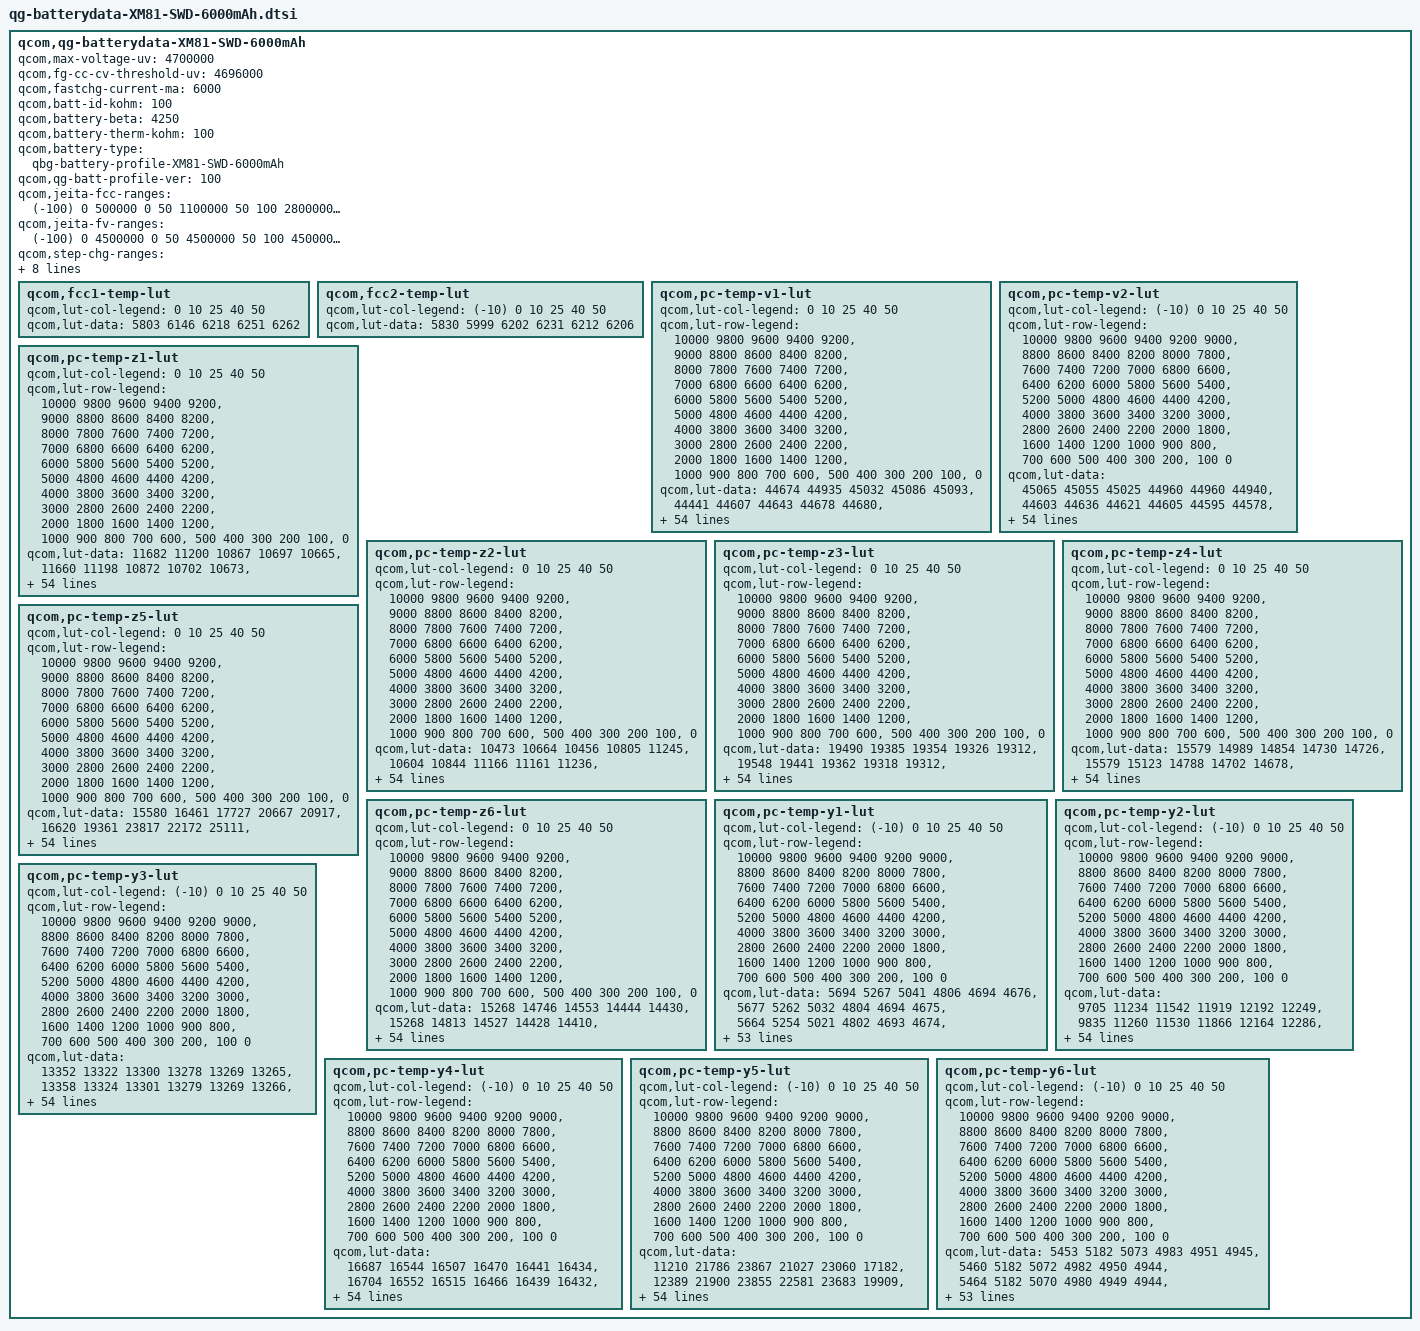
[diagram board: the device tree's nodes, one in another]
/* Copyright (c) 2018, The Linux Foundation. All rights reserved.
 *
 * This program is free software; you can redistribute it and/or modify
 * it under the terms of the GNU General Public License version 2 and
 * only version 2 as published by the Free Software Foundation.
 *
 * This program is distributed in the hope that it will be useful,
 * but WITHOUT ANY WARRANTY; without even the implied warranty of
 * MERCHANTABILITY or FITNESS FOR A PARTICULAR PURPOSE.  See the
 * GNU General Public License for more details.
 */

qcom,qg-batterydata-XM81-SWD-6000mAh {
    /* 7542751_LC_M544_Sunwoda_6000mAH_PM7250B_averaged_MasterSlave_Dec17th2024 */
    qcom,max-voltage-uv = <4700000>;
    qcom,fg-cc-cv-threshold-uv = <4696000>;
    qcom,fastchg-current-ma = <6000>;
    qcom,batt-id-kohm = <100>;
    qcom,battery-beta = <4250>;
    qcom,battery-therm-kohm = <100>;
    qcom,battery-type = "qbg-battery-profile-XM81-SWD-6000mAh";
    qcom,qg-batt-profile-ver = <100>;

    qcom,jeita-fcc-ranges = <(-100)  0   500000
				0   50   1100000
				50  100  2800000
				100 150  3600000
				150 350  6000000
				350 450  6000000
				450 550  2800000>;
	qcom,jeita-fv-ranges = <(-100)   0   4500000
				0   50   4500000
				50  100  4500000
				100 150  4500000
				150 350  4530000
				350 480  4530000
				480 550  4100000>;
	qcom,step-chg-ranges = <3600000  4250000  6000000
				4250001  4500000  5400000
				4500001  4530000  4696000>;
	qcom,vbat-avg-based-step-chg;
	qcom,taper-fcc;

    /* COOL = 15 DegC, WARM = 45 DegC */
	qcom,jeita-soft-thresholds = <0x4621 0x20B8>;
	/* COLD = -10 DegC, HOT = 58 DegC */
	qcom,jeita-hard-thresholds = <0x6226 0x15F7>;
	/* COOL hys = 18 DegC, WARM hys = 42 DegC */
	qcom,jeita-soft-hys-thresholds = <0x4621 0x23C0>;

	qcom,jeita-soft-fcc-ua = <5400000 4500000>;
	qcom,jeita-soft-fv-uv = <4650000 4530000>;

	qcom,fcc1-temp-lut {
		qcom,lut-col-legend = <0 10 25 40 50>;
		qcom,lut-data = <5803 6146 6218 6251 6262>;
	};

	qcom,fcc2-temp-lut {
		qcom,lut-col-legend = <(-10) 0 10 25 40 50>;
		qcom,lut-data = <5830 5999 6202 6231 6212 6206>;
	};

	qcom,pc-temp-v1-lut {
		qcom,lut-col-legend = <0 10 25 40 50>;
		qcom,lut-row-legend = <10000 9800 9600 9400 9200>,
			<9000 8800 8600 8400 8200>,
			<8000 7800 7600 7400 7200>,
			<7000 6800 6600 6400 6200>,
			<6000 5800 5600 5400 5200>,
			<5000 4800 4600 4400 4200>,
			<4000 3800 3600 3400 3200>,
			<3000 2800 2600 2400 2200>,
			<2000 1800 1600 1400 1200>,
			<1000 900 800 700 600>,
			<500 400 300 200 100>,
			<0>;
		qcom,lut-data = <44674 44935 45032 45086 45093>,
			<44441 44607 44643 44678 44680>,
			<44237 44380 44387 44398 44399>,
			<44041 44181 44175 44176 44175>,
			<43834 43973 43971 43967 43968>,
			<43617 43756 43753 43752 43754>,
			<43391 43530 43528 43534 43534>,
			<43156 43292 43293 43306 43305>,
			<42911 43043 43045 43060 43063>,
			<42666 42789 42791 42806 42812>,
			<42417 42528 42532 42550 42558>,
			<42170 42267 42270 42290 42301>,
			<41928 42009 42011 42033 42044>,
			<41689 41754 41754 41776 41788>,
			<41458 41507 41505 41524 41536>,
			<41233 41267 41264 41281 41294>,
			<41015 41036 41031 41044 41058>,
			<40806 40815 40806 40817 40830>,
			<40604 40605 40589 40599 40609>,
			<40408 40408 40384 40390 40398>,
			<40224 40224 40199 40199 40206>,
			<40045 40023 40001 40004 40012>,
			<39855 39797 39742 39768 39782>,
			<39651 39565 39463 39509 39528>,
			<39443 39331 39255 39292 39309>,
			<39226 39104 39092 39112 39123>,
			<39007 38942 38952 38957 38962>,
			<38853 38829 38828 38822 38825>,
			<38752 38730 38718 38703 38705>,
			<38670 38629 38613 38595 38594>,
			<38588 38534 38515 38497 38491>,
			<38511 38451 38427 38406 38396>,
			<38442 38376 38351 38323 38310>,
			<38380 38311 38282 38246 38231>,
			<38325 38254 38221 38180 38161>,
			<38275 38203 38167 38121 38096>,
			<38231 38161 38114 38058 38025>,
			<38189 38127 38068 37993 37945>,
			<38151 38080 38011 37920 37858>,
			<38112 38000 37928 37832 37766>,
			<38052 37897 37824 37729 37664>,
			<37948 37781 37708 37614 37546>,
			<37826 37643 37572 37479 37407>,
			<37692 37478 37406 37317 37243>,
			<37550 37309 37239 37157 37086>,
			<37368 37180 37122 37051 36991>,
			<37282 37141 37092 37024 36965>,
			<37213 37118 37070 37005 36950>,
			<37168 37095 37049 36990 36933>,
			<37118 37065 37015 36952 36887>,
			<37075 36923 36833 36731 36642>,
			<37030 36511 36414 36295 36198>,
			<36967 35912 35828 35707 35611>,
			<36796 35047 35020 34898 34800>,
			<36111 33648 33745 33629 33528>,
			<30000 30000 30000 30000 30000>;
	};

	qcom,pc-temp-v2-lut {
		qcom,lut-col-legend = <(-10) 0 10 25 40 50>;
		qcom,lut-row-legend = <10000 9800 9600 9400 9200 9000>,
			<8800 8600 8400 8200 8000 7800>,
			<7600 7400 7200 7000 6800 6600>,
			<6400 6200 6000 5800 5600 5400>,
			<5200 5000 4800 4600 4400 4200>,
			<4000 3800 3600 3400 3200 3000>,
			<2800 2600 2400 2200 2000 1800>,
			<1600 1400 1200 1000 900 800>,
			<700 600 500 400 300 200>,
			<100 0>;
		qcom,lut-data = <45065 45055 45025 44960 44960 44940>,
			<44603 44636 44621 44605 44595 44578>,
			<44220 44286 44282 44300 44279 44265>,
			<43944 44022 44025 44055 44025 44012>,
			<43749 43826 43827 43856 43819 43805>,
			<43564 43633 43624 43651 43609 43595>,
			<43351 43420 43403 43426 43382 43368>,
			<43129 43201 43173 43192 43147 43134>,
			<42902 42970 42931 42947 42903 42891>,
			<42669 42727 42675 42692 42649 42638>,
			<42433 42479 42418 42434 42393 42384>,
			<42197 42229 42157 42172 42134 42127>,
			<41960 41978 41898 41913 41878 41871>,
			<41723 41731 41645 41657 41625 41620>,
			<41491 41488 41396 41406 41377 41374>,
			<41258 41250 41154 41163 41137 41134>,
			<41015 41025 40915 40927 40904 40900>,
			<40764 40803 40684 40697 40679 40675>,
			<40510 40568 40469 40476 40463 40461>,
			<40247 40321 40255 40259 40252 40254>,
			<39986 40069 40010 40041 40051 40055>,
			<39745 39804 39742 39825 39856 39863>,
			<39522 39543 39488 39590 39637 39646>,
			<39315 39319 39245 39318 39357 39369>,
			<39122 39120 39029 39077 39102 39113>,
			<38942 38943 38855 38904 38928 38939>,
			<38778 38782 38708 38759 38788 38800>,
			<38629 38636 38573 38627 38659 38672>,
			<38491 38504 38449 38508 38542 38554>,
			<38356 38385 38335 38398 38435 38446>,
			<38227 38273 38231 38296 38338 38346>,
			<38122 38164 38134 38202 38248 38254>,
			<38042 38062 38044 38117 38166 38171>,
			<37974 37976 37961 38038 38092 38099>,
			<37908 37899 37886 37962 38013 38018>,
			<37848 37835 37823 37889 37930 37921>,
			<37787 37788 37763 37813 37841 37816>,
			<37725 37747 37703 37726 37738 37702>,
			<37661 37697 37643 37634 37627 37582>,
			<37593 37638 37569 37542 37526 37476>,
			<37521 37566 37475 37452 37440 37388>,
			<37442 37469 37356 37338 37335 37283>,
			<37355 37348 37204 37201 37207 37153>,
			<37258 37210 37043 37053 37076 37020>,
			<37147 37057 36846 36903 36916 36864>,
			<37029 36889 36714 36859 36880 36832>,
			<36971 36803 36659 36835 36866 36818>,
			<36910 36727 36589 36802 36848 36800>,
			<36848 36662 36491 36743 36821 36771>,
			<36791 36598 36298 36570 36731 36674>,
			<36723 36471 35860 36145 36433 36344>,
			<36633 36302 35179 35495 35904 35813>,
			<36483 35868 34414 34584 35206 35110>,
			<36202 35807 33567 33153 34198 34097>,
			<36209 35316 32223 31541 32692 32531>,
			<35983 34759 28774 28591 27756 27768>;
	};

	qcom,pc-temp-z1-lut {
		qcom,lut-col-legend = <0 10 25 40 50>;
		qcom,lut-row-legend = <10000 9800 9600 9400 9200>,
			<9000 8800 8600 8400 8200>,
			<8000 7800 7600 7400 7200>,
			<7000 6800 6600 6400 6200>,
			<6000 5800 5600 5400 5200>,
			<5000 4800 4600 4400 4200>,
			<4000 3800 3600 3400 3200>,
			<3000 2800 2600 2400 2200>,
			<2000 1800 1600 1400 1200>,
			<1000 900 800 700 600>,
			<500 400 300 200 100>,
			<0>;
		qcom,lut-data = <11682 11200 10867 10697 10665>,
			<11660 11198 10872 10702 10673>,
			<11646 11191 10854 10695 10669>,
			<11634 11178 10842 10690 10668>,
			<11626 11166 10831 10687 10667>,
			<11619 11155 10824 10687 10668>,
			<11613 11142 10817 10687 10671>,
			<11604 11123 10813 10687 10673>,
			<11592 11104 10809 10685 10671>,
			<11576 11095 10807 10683 10668>,
			<11547 11091 10804 10682 10668>,
			<11523 11089 10802 10681 10668>,
			<11517 11089 10801 10681 10668>,
			<11515 11088 10799 10680 10668>,
			<11512 11087 10799 10680 10669>,
			<11508 11082 10798 10680 10669>,
			<11505 11080 10798 10681 10670>,
			<11507 11080 10799 10681 10671>,
			<11517 11082 10801 10683 10672>,
			<11526 11084 10803 10684 10673>,
			<11527 11088 10805 10685 10674>,
			<11527 11092 10806 10687 10676>,
			<11529 11099 10808 10688 10677>,
			<11534 11105 10811 10689 10678>,
			<11537 11108 10814 10690 10679>,
			<11537 11109 10817 10693 10682>,
			<11536 11113 10821 10695 10684>,
			<11537 11122 10824 10698 10686>,
			<11554 11130 10829 10701 10687>,
			<11574 11134 10833 10703 10689>,
			<11577 11136 10838 10706 10691>,
			<11575 11139 10842 10708 10693>,
			<11575 11143 10846 10710 10694>,
			<11584 11146 10849 10712 10696>,
			<11598 11148 10853 10715 10698>,
			<11602 11153 10858 10718 10700>,
			<11598 11157 10862 10721 10701>,
			<11596 11167 10867 10725 10703>,
			<11607 11177 10872 10728 10705>,
			<11629 11190 10878 10731 10707>,
			<11650 11202 10884 10733 10709>,
			<11673 11205 10890 10735 10711>,
			<11685 11207 10896 10738 10713>,
			<11684 11221 10902 10740 10714>,
			<11728 11240 10910 10742 10716>,
			<11723 11245 10917 10744 10716>,
			<11726 11245 10916 10745 10717>,
			<11722 11239 10915 10745 10717>,
			<11704 11241 10921 10747 10718>,
			<11731 11242 10922 10750 10720>,
			<11711 11257 10929 10752 10722>,
			<11717 11255 10939 10758 10725>,
			<11734 11268 10950 10763 10730>,
			<11745 11292 10965 10772 10737>,
			<11745 11292 10965 10772 10737>,
			<11745 11292 10965 10772 10737>;
	};

	qcom,pc-temp-z2-lut {
		qcom,lut-col-legend = <0 10 25 40 50>;
		qcom,lut-row-legend = <10000 9800 9600 9400 9200>,
			<9000 8800 8600 8400 8200>,
			<8000 7800 7600 7400 7200>,
			<7000 6800 6600 6400 6200>,
			<6000 5800 5600 5400 5200>,
			<5000 4800 4600 4400 4200>,
			<4000 3800 3600 3400 3200>,
			<3000 2800 2600 2400 2200>,
			<2000 1800 1600 1400 1200>,
			<1000 900 800 700 600>,
			<500 400 300 200 100>,
			<0>;
		qcom,lut-data = <10473 10664 10456 10805 11245>,
			<10604 10844 11166 11161 11236>,
			<10612 10918 11296 11499 11322>,
			<10605 10880 11235 11493 11306>,
			<10589 10842 11149 11449 11270>,
			<10562 10799 11087 11381 11262>,
			<10537 10761 11032 11264 11270>,
			<10521 10735 11020 11183 11275>,
			<10508 10716 11021 11141 11281>,
			<10505 10717 11023 11117 11293>,
			<10506 10745 11028 11122 11305>,
			<10508 10773 11035 11142 11317>,
			<10518 10786 11040 11166 11326>,
			<10543 10797 11052 11194 11332>,
			<10565 10809 11057 11221 11340>,
			<10580 10822 11048 11248 11370>,
			<10593 10834 11037 11275 11418>,
			<10608 10844 11039 11290 11451>,
			<10623 10855 11052 11305 11476>,
			<10639 10946 11055 11315 11497>,
			<10731 11176 11047 11320 11528>,
			<10879 11254 11049 11326 11568>,
			<10912 11087 11126 11339 11633>,
			<10795 10922 11245 11363 11728>,
			<10690 10898 11234 11397 11745>,
			<10696 10880 11073 11461 11598>,
			<10717 10876 10986 11499 11428>,
			<10723 10883 11104 11460 11309>,
			<10712 10889 11248 11374 11216>,
			<10701 10892 11235 11276 11204>,
			<10701 10897 11151 11149 11214>,
			<10708 10900 11108 11100 11229>,
			<10713 10902 11096 11131 11278>,
			<10718 10906 11090 11184 11348>,
			<10723 10916 11104 11241 11425>,
			<10728 10929 11138 11309 11521>,
			<10736 10935 11162 11365 11590>,
			<10741 10938 11180 11411 11651>,
			<10740 10943 11197 11455 11700>,
			<10738 10952 11216 11512 11737>,
			<10738 10959 11231 11563 11765>,
			<10746 10952 11220 11564 11763>,
			<10751 10936 11186 11546 11742>,
			<10753 10934 11187 11531 11715>,
			<11041 10972 11214 11532 11688>,
			<10965 11065 11226 11571 11669>,
			<10958 11059 11179 11553 11677>,
			<10959 11083 11145 11519 11715>,
			<10956 11258 11128 11565 11809>,
			<10903 11844 11124 11665 11887>,
			<10816 11267 11252 11518 11507>,
			<10511 11190 11184 11297 11266>,
			<10465 11018 11098 11202 11195>,
			<10492 10800 10922 11073 11073>,
			<10492 10800 10922 11073 11073>,
			<10492 10800 10922 11073 11073>;
	};

	qcom,pc-temp-z3-lut {
		qcom,lut-col-legend = <0 10 25 40 50>;
		qcom,lut-row-legend = <10000 9800 9600 9400 9200>,
			<9000 8800 8600 8400 8200>,
			<8000 7800 7600 7400 7200>,
			<7000 6800 6600 6400 6200>,
			<6000 5800 5600 5400 5200>,
			<5000 4800 4600 4400 4200>,
			<4000 3800 3600 3400 3200>,
			<3000 2800 2600 2400 2200>,
			<2000 1800 1600 1400 1200>,
			<1000 900 800 700 600>,
			<500 400 300 200 100>,
			<0>;
		qcom,lut-data = <19490 19385 19354 19326 19312>,
			<19548 19441 19362 19318 19312>,
			<19559 19458 19385 19335 19316>,
			<19565 19461 19384 19338 19319>,
			<19568 19461 19383 19339 19319>,
			<19570 19460 19383 19338 19319>,
			<19571 19458 19383 19334 19319>,
			<19569 19456 19383 19331 19319>,
			<19565 19452 19377 19329 19318>,
			<19560 19447 19370 19328 19317>,
			<19555 19438 19365 19325 19315>,
			<19549 19431 19361 19321 19311>,
			<19542 19428 19358 19318 19309>,
			<19535 19426 19356 19317 19308>,
			<19528 19423 19354 19316 19307>,
			<19523 19421 19348 19314 19305>,
			<19519 19418 19343 19311 19302>,
			<19514 19415 19342 19310 19300>,
			<19508 19412 19342 19307 19298>,
			<19506 19412 19341 19306 19297>,
			<19509 19416 19340 19304 19295>,
			<19514 19417 19339 19303 19294>,
			<19516 19420 19345 19304 19294>,
			<19515 19422 19356 19307 19296>,
			<19515 19421 19356 19309 19300>,
			<19518 19419 19343 19311 19310>,
			<19523 19417 19336 19314 19317>,
			<19524 19414 19341 19322 19317>,
			<19520 19412 19349 19332 19317>,
			<19515 19414 19355 19332 19316>,
			<19513 19419 19361 19325 19313>,
			<19512 19420 19363 19320 19310>,
			<19511 19420 19360 19317 19306>,
			<19511 19419 19356 19315 19302>,
			<19510 19419 19353 19311 19299>,
			<19509 19418 19352 19308 19295>,
			<19508 19417 19350 19307 19294>,
			<19507 19415 19349 19307 19294>,
			<19505 19414 19348 19307 19295>,
			<19501 19411 19346 19307 19295>,
			<19497 19408 19343 19307 19296>,
			<19492 19407 19341 19307 19297>,
			<19487 19405 19340 19305 19298>,
			<19483 19403 19339 19305 19301>,
			<19395 19395 19338 19305 19302>,
			<19439 19384 19333 19301 19294>,
			<19439 19383 19329 19300 19293>,
			<19418 19373 19328 19299 19289>,
			<19307 19339 19328 19296 19285>,
			<19294 19302 19328 19292 19286>,
			<19288 19342 19320 19300 19297>,
			<19271 19334 19324 19307 19302>,
			<19283 19354 19329 19310 19302>,
			<19330 19405 19339 19312 19303>,
			<19330 19405 19339 19312 19303>,
			<19330 19405 19339 19312 19303>;
	};

	qcom,pc-temp-z4-lut {
		qcom,lut-col-legend = <0 10 25 40 50>;
		qcom,lut-row-legend = <10000 9800 9600 9400 9200>,
			<9000 8800 8600 8400 8200>,
			<8000 7800 7600 7400 7200>,
			<7000 6800 6600 6400 6200>,
			<6000 5800 5600 5400 5200>,
			<5000 4800 4600 4400 4200>,
			<4000 3800 3600 3400 3200>,
			<3000 2800 2600 2400 2200>,
			<2000 1800 1600 1400 1200>,
			<1000 900 800 700 600>,
			<500 400 300 200 100>,
			<0>;
		qcom,lut-data = <15579 14989 14854 14730 14726>,
			<15579 15123 14788 14702 14678>,
			<15423 15165 14887 14744 14698>,
			<15209 15000 14845 14737 14703>,
			<15079 14894 14788 14716 14693>,
			<14992 14837 14756 14700 14682>,
			<14924 14796 14732 14688 14670>,
			<14872 14763 14713 14678 14662>,
			<14830 14738 14699 14672 14657>,
			<14798 14720 14689 14667 14654>,
			<14772 14706 14682 14663 14651>,
			<14751 14696 14677 14660 14648>,
			<14734 14688 14671 14655 14645>,
			<14719 14683 14663 14650 14641>,
			<14710 14677 14659 14645 14636>,
			<14706 14673 14657 14640 14633>,
			<14702 14669 14655 14636 14630>,
			<14700 14668 14651 14633 14627>,
			<14698 14666 14647 14630 14623>,
			<14695 14659 14644 14627 14621>,
			<14684 14647 14643 14626 14620>,
			<14669 14644 14642 14625 14619>,
			<14666 14658 14661 14641 14631>,
			<14680 14679 14698 14681 14666>,
			<14699 14705 14721 14694 14677>,
			<14722 14736 14737 14696 14671>,
			<14752 14742 14743 14696 14663>,
			<14762 14731 14729 14682 14655>,
			<14756 14717 14707 14660 14647>,
			<14747 14705 14690 14651 14641>,
			<14740 14694 14674 14647 14636>,
			<14733 14688 14666 14644 14633>,
			<14727 14683 14661 14640 14630>,
			<14722 14682 14659 14636 14627>,
			<14718 14681 14659 14634 14626>,
			<14715 14681 14659 14633 14624>,
			<14712 14680 14659 14634 14625>,
			<14709 14677 14660 14639 14632>,
			<14701 14674 14662 14644 14638>,
			<14690 14672 14665 14646 14637>,
			<14681 14670 14668 14647 14636>,
			<14675 14664 14665 14645 14633>,
			<14667 14654 14656 14639 14627>,
			<14653 14648 14652 14638 14627>,
			<14702 14639 14646 14638 14627>,
			<14642 14627 14634 14630 14622>,
			<14642 14624 14631 14625 14618>,
			<14667 14629 14623 14615 14612>,
			<14792 14662 14613 14607 14603>,
			<14805 14701 14612 14609 14602>,
			<14809 14660 14633 14614 14605>,
			<14827 14677 14634 14612 14605>,
			<14817 14663 14631 14610 14606>,
			<14784 14637 14625 14609 14607>,
			<14784 14637 14625 14609 14607>,
			<14784 14637 14625 14609 14607>;
	};

	qcom,pc-temp-z5-lut {
		qcom,lut-col-legend = <0 10 25 40 50>;
		qcom,lut-row-legend = <10000 9800 9600 9400 9200>,
			<9000 8800 8600 8400 8200>,
			<8000 7800 7600 7400 7200>,
			<7000 6800 6600 6400 6200>,
			<6000 5800 5600 5400 5200>,
			<5000 4800 4600 4400 4200>,
			<4000 3800 3600 3400 3200>,
			<3000 2800 2600 2400 2200>,
			<2000 1800 1600 1400 1200>,
			<1000 900 800 700 600>,
			<500 400 300 200 100>,
			<0>;
		qcom,lut-data = <15580 16461 17727 20667 20917>,
			<16620 19361 23817 22172 25111>,
			<17484 18786 21345 23631 25185>,
			<18295 20058 21721 24185 25284>,
			<19210 21233 22363 25270 25492>,
			<20269 22284 23229 25357 25939>,
			<21344 23272 24369 24964 27132>,
			<22356 24159 25005 24789 28263>,
			<23343 24965 25376 25516 29160>,
			<24301 25599 25572 26308 29778>,
			<25251 26065 25513 26041 29478>,
			<26301 26611 25381 25257 28440>,
			<27704 27465 25772 25143 28191>,
			<29428 28513 27332 26300 29794>,
			<30537 29603 28075 27443 31148>,
			<31125 30800 27153 28134 30843>,
			<31460 31732 26135 28714 30245>,
			<31456 32257 26690 28861 30399>,
			<31530 32851 28579 29362 31957>,
			<31983 34598 30131 30125 33491>,
			<34655 38344 31152 31735 34761>,
			<39487 42409 32678 33085 35644>,
			<43566 48921 40344 32520 33836>,
			<47771 53672 51373 30474 28340>,
			<51491 50933 50014 27775 25328>,
			<54343 43524 33302 23039 23995>,
			<56767 37951 24073 20196 23392>,
			<57128 33307 24245 23459 24500>,
			<51061 30946 24668 28638 26998>,
			<44373 32648 26653 29768 29339>,
			<43615 36419 32151 29933 31860>,
			<43964 39849 36649 30310 33575>,
			<44320 43376 39610 32889 34980>,
			<45137 46388 42342 36154 35991>,
			<46326 49183 45799 38276 36659>,
			<47029 51221 49081 40101 38098>,
			<47683 51250 49661 40466 38080>,
			<48142 50478 48934 39880 36324>,
			<48203 49644 47674 38929 34738>,
			<48101 48246 43237 36821 34016>,
			<48031 46876 37678 34089 33545>,
			<47552 46472 35964 32789 34413>,
			<47119 46466 35249 32061 37662>,
			<47503 45295 34414 30799 38392>,
			<30145 44557 34161 29238 37152>,
			<40211 44759 35993 27811 29080>,
			<40216 43830 33484 28825 29857>,
			<31803 31167 33710 33765 29793>,
			<12882 17783 39173 35190 35745>,
			<12405 13698 38956 30591 36336>,
			<12202 19775 24341 27961 41555>,
			<11792 16562 22752 31195 45204>,
			<12007 23678 23798 33528 41673>,
			<13774 61510 29494 35807 40428>,
			<13774 61510 29494 35807 40428>,
			<13774 61510 29494 35807 40428>;
	};

	qcom,pc-temp-z6-lut {
		qcom,lut-col-legend = <0 10 25 40 50>;
		qcom,lut-row-legend = <10000 9800 9600 9400 9200>,
			<9000 8800 8600 8400 8200>,
			<8000 7800 7600 7400 7200>,
			<7000 6800 6600 6400 6200>,
			<6000 5800 5600 5400 5200>,
			<5000 4800 4600 4400 4200>,
			<4000 3800 3600 3400 3200>,
			<3000 2800 2600 2400 2200>,
			<2000 1800 1600 1400 1200>,
			<1000 900 800 700 600>,
			<500 400 300 200 100>,
			<0>;
		qcom,lut-data = <15268 14746 14553 14444 14430>,
			<15268 14813 14527 14428 14410>,
			<15189 14832 14577 14454 14420>,
			<15076 14751 14556 14452 14424>,
			<15004 14696 14527 14444 14419>,
			<14954 14664 14512 14436 14415>,
			<14912 14639 14500 14428 14410>,
			<14876 14618 14489 14423 14406>,
			<14845 14601 14478 14419 14404>,
			<14819 14586 14470 14416 14401>,
			<14796 14574 14464 14412 14399>,
			<14777 14565 14459 14408 14396>,
			<14761 14559 14454 14405 14393>,
			<14747 14554 14450 14402 14391>,
			<14739 14550 14446 14399 14388>,
			<14733 14546 14442 14395 14385>,
			<14729 14543 14439 14392 14383>,
			<14726 14541 14436 14390 14380>,
			<14723 14538 14435 14387 14378>,
			<14721 14536 14433 14386 14376>,
			<14720 14534 14432 14385 14375>,
			<14718 14534 14432 14384 14374>,
			<14719 14542 14444 14391 14379>,
			<14726 14553 14468 14409 14396>,
			<14736 14566 14475 14418 14404>,
			<14750 14579 14476 14421 14406>,
			<14767 14581 14477 14422 14408>,
			<14773 14576 14474 14421 14406>,
			<14771 14571 14470 14417 14402>,
			<14767 14569 14467 14413 14398>,
			<14765 14568 14464 14409 14395>,
			<14763 14567 14462 14405 14392>,
			<14761 14566 14459 14402 14389>,
			<14762 14566 14457 14399 14386>,
			<14763 14567 14457 14397 14383>,
			<14764 14568 14457 14395 14381>,
			<14766 14569 14457 14395 14381>,
			<14768 14569 14458 14397 14384>,
			<14769 14570 14459 14400 14387>,
			<14770 14571 14461 14401 14387>,
			<14771 14572 14462 14402 14387>,
			<14773 14571 14461 14401 14387>,
			<14776 14570 14458 14398 14385>,
			<14779 14569 14457 14399 14386>,
			<14769 14567 14456 14399 14387>,
			<14771 14560 14450 14393 14381>,
			<14775 14559 14448 14391 14379>,
			<14776 14555 14444 14387 14375>,
			<14773 14554 14440 14381 14369>,
			<14775 14554 14441 14381 14369>,
			<14775 14561 14448 14388 14377>,
			<14778 14568 14454 14391 14380>,
			<14787 14579 14458 14393 14382>,
			<14804 14602 14465 14396 14384>,
			<14804 14602 14465 14396 14384>,
			<14804 14602 14465 14396 14384>;
	};

	qcom,pc-temp-y1-lut {
		qcom,lut-col-legend = <(-10) 0 10 25 40 50>;
		qcom,lut-row-legend = <10000 9800 9600 9400 9200 9000>,
			<8800 8600 8400 8200 8000 7800>,
			<7600 7400 7200 7000 6800 6600>,
			<6400 6200 6000 5800 5600 5400>,
			<5200 5000 4800 4600 4400 4200>,
			<4000 3800 3600 3400 3200 3000>,
			<2800 2600 2400 2200 2000 1800>,
			<1600 1400 1200 1000 900 800>,
			<700 600 500 400 300 200>,
			<100 0>;
		qcom,lut-data = <5694 5267 5041 4806 4694 4676>,
			<5677 5262 5032 4804 4694 4675>,
			<5664 5254 5021 4802 4693 4674>,
			<5656 5246 5009 4799 4692 4672>,
			<5649 5240 5000 4796 4691 4671>,
			<5645 5237 4998 4794 4690 4670>,
			<5643 5237 4999 4791 4688 4670>,
			<5644 5238 5001 4788 4686 4670>,
			<5646 5239 4998 4785 4685 4670>,
			<5656 5242 4991 4783 4683 4670>,
			<5665 5244 4987 4781 4682 4670>,
			<5663 5245 4985 4780 4682 4669>,
			<5654 5247 4983 4779 4681 4669>,
			<5645 5245 4982 4776 4680 4669>,
			<5634 5236 4981 4773 4679 4669>,
			<5626 5230 4978 4772 4679 4669>,
			<5626 5235 4975 4771 4680 4669>,
			<5631 5243 4974 4771 4680 4669>,
			<5635 5245 4976 4772 4680 4670>,
			<5640 5246 4980 4773 4680 4670>,
			<5646 5246 4979 4772 4680 4670>,
			<5647 5241 4976 4771 4680 4671>,
			<5643 5233 4975 4771 4680 4671>,
			<5641 5234 4981 4773 4681 4672>,
			<5643 5241 4987 4775 4683 4673>,
			<5649 5247 4989 4777 4684 4673>,
			<5653 5249 4989 4778 4685 4674>,
			<5656 5249 4989 4779 4686 4674>,
			<5658 5250 4990 4781 4687 4675>,
			<5657 5248 4991 4783 4688 4677>,
			<5657 5249 4992 4785 4689 4678>,
			<5657 5255 4994 4788 4690 4679>,
			<5664 5262 4997 4789 4692 4680>,
			<5672 5262 5001 4791 4694 4681>,
			<5672 5258 5004 4793 4695 4682>,
			<5665 5254 5007 4796 4696 4683>,
			<5657 5257 5009 4799 4697 4683>,
			<5650 5262 5010 4801 4698 4684>,
			<5644 5266 5011 4803 4699 4685>,
			<5644 5272 5013 4806 4700 4686>,
			<5653 5276 5015 4809 4702 4687>,
			<5660 5276 5019 4810 4703 4688>,
			<5663 5278 5028 4811 4704 4689>,
			<5667 5290 5030 4816 4704 4690>,
			<5672 5282 5035 4817 4707 4692>,
			<5673 5282 5048 4821 4709 4692>,
			<5666 5290 5040 4823 4710 4692>,
			<5667 5294 5055 4829 4711 4693>,
			<5675 5304 5069 4832 4711 4693>,
			<5714 5365 5164 4837 4711 4693>,
			<5817 5438 5246 4850 4712 4695>,
			<5886 5503 5310 4866 4715 4697>,
			<5979 5581 5310 4889 4720 4700>,
			<6001 5581 5310 4971 4725 4705>,
			<6001 5581 5310 4971 4725 4705>,
			<6001 5581 5310 4971 4725 4705>;
	};

	qcom,pc-temp-y2-lut {
		qcom,lut-col-legend = <(-10) 0 10 25 40 50>;
		qcom,lut-row-legend = <10000 9800 9600 9400 9200 9000>,
			<8800 8600 8400 8200 8000 7800>,
			<7600 7400 7200 7000 6800 6600>,
			<6400 6200 6000 5800 5600 5400>,
			<5200 5000 4800 4600 4400 4200>,
			<4000 3800 3600 3400 3200 3000>,
			<2800 2600 2400 2200 2000 1800>,
			<1600 1400 1200 1000 900 800>,
			<700 600 500 400 300 200>,
			<100 0>;
		qcom,lut-data = <9705 11234 11542 11919 12192 12249>,
			<9835 11260 11530 11866 12164 12286>,
			<10117 11270 11514 11803 12125 12295>,
			<10453 11269 11494 11741 12080 12282>,
			<10744 11259 11471 11690 12031 12252>,
			<10891 11244 11446 11660 11979 12212>,
			<10898 11216 11418 11646 11909 12127>,
			<10900 11180 11388 11632 11853 12032>,
			<10903 11152 11351 11591 11841 11970>,
			<10913 11127 11309 11527 11842 11920>,
			<10926 11116 11291 11510 11835 11898>,
			<10940 11118 11283 11516 11798 11904>,
			<10956 11126 11280 11523 11771 11913>,
			<10976 11137 11290 11527 11781 11891>,
			<11007 11162 11313 11530 11802 11853>,
			<11041 11195 11336 11547 11810 11847>,
			<11068 11237 11368 11584 11808 11860>,
			<11093 11284 11407 11633 11805 11868>,
			<11106 11317 11480 11703 11807 11882>,
			<11109 11348 11547 11786 11822 11908>,
			<11110 11362 11550 11875 11924 11939>,
			<11115 11340 11537 11967 12156 11989>,
			<11134 11304 11533 11981 12236 12056>,
			<11149 11310 11546 11883 12187 12172>,
			<11149 11374 11567 11797 12143 12289>,
			<11148 11426 11591 11787 12163 12363>,
			<11146 11441 11620 11794 12215 12424>,
			<11132 11451 11636 11821 12253 12468>,
			<11109 11462 11648 11895 12281 12506>,
			<11087 11476 11658 11933 12306 12550>,
			<11060 11482 11677 11922 12326 12639>,
			<11004 11480 11698 11910 12347 12728>,
			<10572 11473 11698 11940 12383 12730>,
			<10025 11437 11684 12027 12435 12692>,
			<9856 11261 11669 12052 12456 12675>,
			<9789 11128 11649 11988 12420 12699>,
			<9749 11175 11619 11924 12384 12724>,
			<9725 11266 11559 11900 12399 12694>,
			<9707 11252 11453 11883 12429 12610>,
			<9695 11162 11384 11891 12423 12574>,
			<9686 11036 11355 11939 12317 12577>,
			<9680 10791 11291 11936 12284 12554>,
			<9675 10463 11121 11900 12323 12479>,
			<9671 9962 10920 11877 12326 12439>,
			<9667 9743 10369 11747 12344 12457>,
			<9664 9693 9964 11672 12216 12265>,
			<9662 9678 9776 11677 12222 12151>,
			<9660 9667 9680 11649 12066 12049>,
			<9657 9659 9657 11610 11984 12055>,
			<9653 9652 9652 11452 11951 11869>,
			<9650 9649 9651 11198 11820 11797>,
			<9648 9649 9650 10852 11720 11760>,
			<9648 9650 9651 10286 11615 11619>,
			<9649 9653 9652 9708 11487 11461>,
			<9649 9653 9652 9708 11487 11461>,
			<9649 9653 9652 9708 11487 11461>;
	};

	qcom,pc-temp-y3-lut {
		qcom,lut-col-legend = <(-10) 0 10 25 40 50>;
		qcom,lut-row-legend = <10000 9800 9600 9400 9200 9000>,
			<8800 8600 8400 8200 8000 7800>,
			<7600 7400 7200 7000 6800 6600>,
			<6400 6200 6000 5800 5600 5400>,
			<5200 5000 4800 4600 4400 4200>,
			<4000 3800 3600 3400 3200 3000>,
			<2800 2600 2400 2200 2000 1800>,
			<1600 1400 1200 1000 900 800>,
			<700 600 500 400 300 200>,
			<100 0>;
		qcom,lut-data = <13352 13322 13300 13278 13269 13265>,
			<13358 13324 13301 13279 13269 13266>,
			<13369 13326 13301 13279 13269 13266>,
			<13381 13327 13302 13280 13269 13267>,
			<13392 13329 13303 13281 13269 13267>,
			<13398 13331 13303 13281 13270 13267>,
			<13398 13332 13304 13281 13270 13268>,
			<13397 13334 13305 13282 13270 13268>,
			<13397 13335 13306 13282 13270 13268>,
			<13398 13336 13306 13282 13271 13268>,
			<13398 13336 13305 13282 13271 13269>,
			<13398 13337 13306 13282 13272 13269>,
			<13397 13337 13306 13281 13272 13270>,
			<13396 13336 13307 13282 13272 13270>,
			<13395 13335 13308 13282 13272 13270>,
			<13394 13334 13308 13282 13272 13270>,
			<13392 13334 13307 13284 13274 13270>,
			<13387 13334 13307 13285 13275 13270>,
			<13382 13334 13306 13286 13275 13271>,
			<13376 13331 13306 13287 13274 13272>,
			<13370 13328 13305 13287 13275 13273>,
			<13366 13325 13302 13286 13277 13274>,
			<13362 13321 13300 13285 13277 13274>,
			<13358 13318 13297 13282 13273 13270>,
			<13355 13316 13295 13279 13269 13267>,
			<13352 13314 13294 13278 13269 13266>,
			<13350 13313 13294 13278 13269 13266>,
			<13348 13311 13294 13278 13269 13266>,
			<13346 13310 13293 13278 13268 13267>,
			<13340 13310 13293 13278 13268 13267>,
			<13328 13309 13293 13278 13268 13266>,
			<13322 13308 13292 13277 13269 13266>,
			<13324 13306 13292 13277 13269 13266>,
			<13328 13304 13291 13278 13268 13266>,
			<13332 13299 13291 13278 13268 13266>,
			<13341 13296 13291 13278 13268 13266>,
			<13352 13301 13291 13277 13269 13266>,
			<13364 13310 13291 13277 13268 13266>,
			<13378 13314 13292 13276 13268 13265>,
			<13397 13317 13293 13276 13268 13265>,
			<13425 13319 13295 13276 13268 13266>,
			<13461 13321 13296 13276 13267 13266>,
			<13511 13323 13299 13277 13267 13266>,
			<13582 13333 13302 13276 13268 13267>,
			<13683 13358 13304 13275 13267 13266>,
			<13846 13408 13320 13278 13269 13267>,
			<13980 13466 13357 13279 13269 13268>,
			<14146 13606 13481 13281 13271 13269>,
			<14442 14012 14262 13286 13274 13271>,
			<15460 16207 19453 13288 13273 13271>,
			<19271 25100 43576 13291 13272 13270>,
			<30289 60066 65535 13301 13273 13270>,
			<65535 65535 65535 13366 13274 13271>,
			<65535 65535 65535 16067 13276 13272>,
			<65535 65535 65535 16067 13276 13272>,
			<65535 65535 65535 16067 13276 13272>;
	};

	qcom,pc-temp-y4-lut {
		qcom,lut-col-legend = <(-10) 0 10 25 40 50>;
		qcom,lut-row-legend = <10000 9800 9600 9400 9200 9000>,
			<8800 8600 8400 8200 8000 7800>,
			<7600 7400 7200 7000 6800 6600>,
			<6400 6200 6000 5800 5600 5400>,
			<5200 5000 4800 4600 4400 4200>,
			<4000 3800 3600 3400 3200 3000>,
			<2800 2600 2400 2200 2000 1800>,
			<1600 1400 1200 1000 900 800>,
			<700 600 500 400 300 200>,
			<100 0>;
		qcom,lut-data = <16687 16544 16507 16470 16441 16434>,
			<16704 16552 16515 16466 16439 16432>,
			<16726 16568 16522 16462 16435 16429>,
			<16749 16586 16526 16457 16432 16426>,
			<16770 16602 16528 16454 16429 16424>,
			<16783 16609 16529 16452 16428 16423>,
			<16791 16609 16527 16451 16428 16422>,
			<16800 16609 16524 16451 16428 16422>,
			<16802 16607 16521 16452 16428 16423>,
			<16802 16602 16517 16454 16429 16423>,
			<16801 16598 16516 16457 16430 16424>,
			<16803 16599 16517 16460 16432 16424>,
			<16809 16602 16518 16465 16434 16425>,
			<16816 16607 16523 16469 16437 16427>,
			<16824 16622 16531 16475 16441 16430>,
			<16831 16641 16543 16481 16444 16433>,
			<16830 16667 16561 16488 16447 16437>,
			<16818 16692 16582 16497 16451 16441>,
			<16802 16695 16615 16511 16459 16445>,
			<16773 16686 16643 16527 16469 16450>,
			<16733 16671 16637 16542 16484 16460>,
			<16702 16635 16602 16558 16504 16477>,
			<16675 16586 16565 16556 16507 16481>,
			<16651 16556 16520 16502 16472 16456>,
			<16630 16535 16485 16455 16438 16431>,
			<16612 16522 16477 16449 16433 16428>,
			<16595 16514 16472 16445 16431 16427>,
			<16577 16509 16472 16445 16431 16427>,
			<16563 16506 16472 16448 16433 16428>,
			<16560 16505 16473 16451 16436 16430>,
			<16558 16503 16475 16456 16440 16433>,
			<16558 16497 16477 16462 16445 16438>,
			<16570 16490 16477 16468 16452 16444>,
			<16587 16490 16477 16474 16460 16451>,
			<16597 16501 16477 16477 16463 16453>,
			<16603 16508 16478 16478 16460 16449>,
			<16609 16511 16480 16479 16456 16442>,
			<16617 16515 16485 16470 16448 16436>,
			<16624 16522 16493 16454 16436 16431>,
			<16631 16538 16496 16449 16432 16430>,
			<16638 16549 16496 16449 16433 16429>,
			<16644 16550 16495 16447 16433 16428>,
			<16647 16551 16493 16446 16430 16425>,
			<16649 16560 16500 16450 16432 16427>,
			<16651 16571 16499 16439 16421 16415>,
			<16651 16565 16528 16451 16428 16423>,
			<16651 16569 16555 16463 16434 16427>,
			<16649 16581 16598 16479 16440 16435>,
			<16652 16602 16692 16503 16449 16449>,
			<16692 16707 17691 16504 16455 16454>,
			<16978 17829 29770 16504 16436 16428>,
			<18149 23365 65535 16534 16432 16427>,
			<18983 65535 65535 16639 16440 16432>,
			<53511 65535 65535 17592 16465 16453>,
			<53511 65535 65535 17592 16465 16453>,
			<53511 65535 65535 17592 16465 16453>;
	};

	qcom,pc-temp-y5-lut {
		qcom,lut-col-legend = <(-10) 0 10 25 40 50>;
		qcom,lut-row-legend = <10000 9800 9600 9400 9200 9000>,
			<8800 8600 8400 8200 8000 7800>,
			<7600 7400 7200 7000 6800 6600>,
			<6400 6200 6000 5800 5600 5400>,
			<5200 5000 4800 4600 4400 4200>,
			<4000 3800 3600 3400 3200 3000>,
			<2800 2600 2400 2200 2000 1800>,
			<1600 1400 1200 1000 900 800>,
			<700 600 500 400 300 200>,
			<100 0>;
		qcom,lut-data = <11210 21786 23867 21027 23060 17182>,
			<12389 21900 23855 22581 23683 19909>,
			<14549 22015 23823 23601 24049 22845>,
			<17022 22117 23776 24191 24224 25486>,
			<19137 22189 23722 24457 24273 27327>,
			<20220 22215 23663 24477 24245 27869>,
			<20288 22196 23561 23656 23707 27325>,
			<20264 22150 23382 22402 22945 26546>,
			<20251 22036 22864 21342 22430 25778>,
			<20271 21638 21817 20263 21921 24604>,
			<20298 21153 21003 19299 21346 23894>,
			<20309 20562 20115 18407 20674 23580>,
			<20312 19846 19375 17667 19942 23237>,
			<20335 19195 19032 17010 18979 22513>,
			<20770 18508 18755 16506 18072 21460>,
			<21445 18176 18288 16470 18068 20324>,
			<21937 18603 17509 16631 18798 18933>,
			<22382 19544 17126 16799 19192 18301>,
			<22662 20690 17652 16918 18205 18495>,
			<22757 22380 18763 17096 17004 18858>,
			<22822 23436 20651 17948 17316 19213>,
			<22975 23613 23741 20032 18814 19633>,
			<23388 23725 25033 22075 20191 20242>,
			<23728 23950 25146 24395 21329 21399>,
			<23697 24346 25248 25739 22382 22671>,
			<23506 24562 25625 25663 23473 23821>,
			<23509 24227 26215 25469 24433 24878>,
			<23946 23706 26475 25367 24408 24998>,
			<24359 23680 26541 25214 23061 24128>,
			<22829 24075 26552 24980 22105 22966>,
			<18002 24330 26524 24306 22000 21331>,
			<15124 23730 26483 23654 21928 19771>,
			<14380 22537 26489 24125 21717 19697>,
			<13965 21198 26535 25585 21326 20317>,
			<13945 18746 26530 26123 21234 21051>,
			<14072 17254 26123 26084 22820 21968>,
			<14196 20000 25680 26060 24531 22804>,
			<14265 24454 25733 26529 24822 23203>,
			<14327 25378 25960 27322 24907 23515>,
			<14404 25035 26027 27312 24703 23921>,
			<14515 24819 25875 26431 23456 24597>,
			<14587 23121 25514 25743 22741 25147>,
			<14564 20650 24392 25016 22091 25500>,
			<14483 16869 22343 23758 23212 25049>,
			<14134 14827 18599 23380 27008 32410>,
			<13859 14732 15338 23686 23361 24744>,
			<13873 14591 15166 21493 21225 24404>,
			<13682 14174 14554 20311 21486 23658>,
			<13218 13974 13897 20390 23813 23927>,
			<12772 12856 10747 20957 21773 21991>,
			<11138 9961 9092 21695 22818 26628>,
			<10113 9450 8820 20128 26443 29406>,
			<15139 8893 8751 16654 27751 29271>,
			<32184 8728 8734 11521 29081 27244>,
			<32184 8728 8734 11521 29081 27244>,
			<32184 8728 8734 11521 29081 27244>;
	};

	qcom,pc-temp-y6-lut {
		qcom,lut-col-legend = <(-10) 0 10 25 40 50>;
		qcom,lut-row-legend = <10000 9800 9600 9400 9200 9000>,
			<8800 8600 8400 8200 8000 7800>,
			<7600 7400 7200 7000 6800 6600>,
			<6400 6200 6000 5800 5600 5400>,
			<5200 5000 4800 4600 4400 4200>,
			<4000 3800 3600 3400 3200 3000>,
			<2800 2600 2400 2200 2000 1800>,
			<1600 1400 1200 1000 900 800>,
			<700 600 500 400 300 200>,
			<100 0>;
		qcom,lut-data = <5453 5182 5073 4983 4951 4945>,
			<5460 5182 5072 4982 4950 4944>,
			<5464 5182 5070 4980 4949 4944>,
			<5466 5181 5068 4979 4948 4943>,
			<5467 5180 5066 4978 4948 4943>,
			<5466 5178 5064 4977 4947 4942>,
			<5464 5177 5062 4976 4947 4943>,
			<5460 5174 5060 4976 4948 4943>,
			<5456 5171 5057 4976 4948 4943>,
			<5452 5167 5053 4976 4948 4943>,
			<5449 5164 5051 4976 4949 4944>,
			<5445 5161 5050 4977 4949 4944>,
			<5442 5159 5049 4978 4950 4945>,
			<5441 5159 5050 4979 4951 4946>,
			<5441 5161 5052 4980 4952 4947>,
			<5441 5163 5054 4982 4954 4948>,
			<5439 5169 5058 4985 4955 4949>,
			<5431 5176 5063 4989 4957 4950>,
			<5420 5177 5071 4993 4959 4952>,
			<5408 5172 5078 4998 4962 4954>,
			<5395 5166 5076 5002 4967 4957>,
			<5385 5153 5064 5006 4973 4963>,
			<5376 5136 5052 5005 4975 4964>,
			<5370 5126 5037 4987 4961 4954>,
			<5365 5120 5026 4972 4949 4944>,
			<5362 5116 5024 4970 4947 4943>,
			<5360 5115 5023 4968 4947 4943>,
			<5360 5114 5023 4969 4947 4943>,
			<5361 5114 5024 4970 4947 4943>,
			<5362 5116 5025 4971 4948 4944>,
			<5362 5117 5027 4972 4950 4945>,
			<5364 5117 5028 4974 4951 4946>,
			<5374 5118 5029 4976 4953 4948>,
			<5390 5119 5030 4979 4956 4950>,
			<5406 5123 5031 4980 4956 4951>,
			<5425 5128 5033 4981 4956 4950>,
			<5447 5138 5036 4981 4955 4948>,
			<5472 5152 5040 4979 4953 4946>,
			<5501 5167 5046 4974 4949 4944>,
			<5535 5184 5052 4973 4948 4944>,
			<5576 5203 5057 4974 4948 4945>,
			<5625 5225 5065 4974 4948 4945>,
			<5681 5252 5077 4975 4948 4944>,
			<5751 5291 5098 4976 4949 4945>,
			<5845 5351 5117 4973 4945 4941>,
			<5991 5437 5194 4981 4948 4944>,
			<6108 5521 5290 4986 4951 4946>,
			<6254 5675 5491 4993 4954 4949>,
			<6510 6049 6234 5006 4959 4955>,
			<7364 7814 10420 5011 4960 4956>,
			<10335 14464 30458 5019 4954 4948>,
			<18278 38686 65535 5051 4953 4948>,
			<42301 65535 65535 5185 4957 4951>,
			<65535 65535 65535 7637 4967 4959>,
			<65535 65535 65535 7637 4967 4959>,
			<65535 65535 65535 7637 4967 4959>;
	};

};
